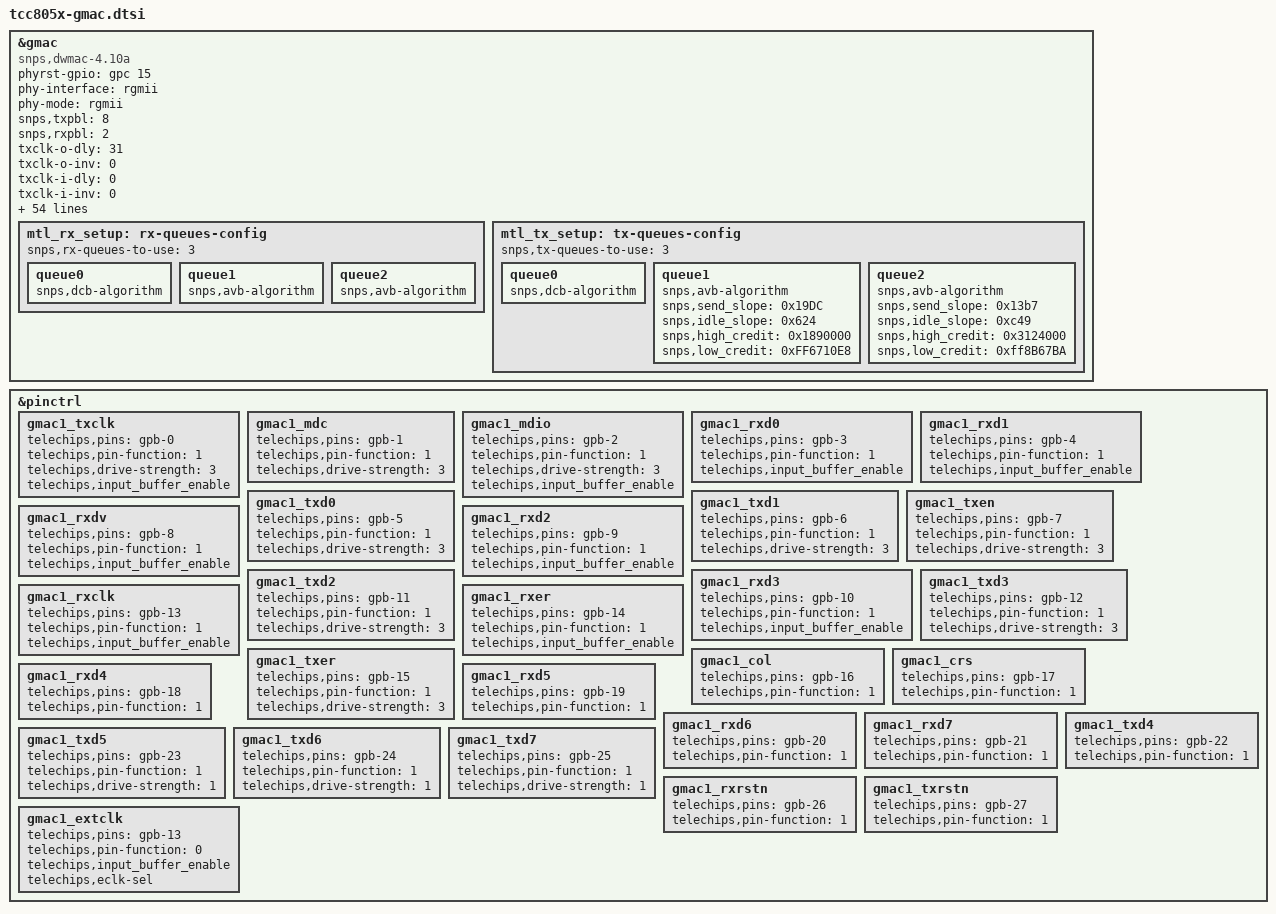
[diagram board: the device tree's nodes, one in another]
// SPDX-License-Identifier: (GPL-2.0-or-later OR MIT)
/*
 * Copyright (C) 2023 Telechips Inc.
 */

&gmac {
	status = "okay";
	compatible = "snps,dwmac-4.10a","telechips,gmac";
	phyrst-gpio = <&gpc 15 0>;
	phy-interface = "rgmii";
	interrupt-names = "macirq";
	phy-mode = "rgmii";
	snps,txpbl = <8>;
	snps,rxpbl = <2>;
	//ecid-mac-addr;
	txclk-o-dly = <31>;
	txclk-o-inv = <0>;
	txclk-i-dly = <0>;
	txclk-i-inv = <0>;
	txen-dly = <0>;
	txer-dly = <0>;
	txd0-dly = <0>;
	txd1-dly = <0>;
	txd2-dly = <0>;
	txd3-dly = <0>;
	txd4-dly = <0>;
	txd5-dly = <0>;
	txd6-dly = <0>;
	txd7-dly = <0>;
	rxclk-i-dly = <0>;
	rxclk-i-inv = <0>;
	rxdv-dly = <0>;
	rxer-dly = <0>;
	rxd0-dly = <0>;
	rxd1-dly = <0>;
	rxd2-dly = <0>;
	rxd3-dly = <0>;
	rxd4-dly = <0>;
	rxd5-dly = <0>;
	rxd6-dly = <0>;
	rxd7-dly = <0>;
	crs-dly = <0>;
	col-dly = <0>;
	pinctrl-names = "default", "mii", "rmii-ext","rmii", "gmii", "rgmii","sleep";
	pinctrl-0 = <>;
	pinctrl-1 = <&gmac1_mdc &gmac1_mdio
		&gmac1_txclk &gmac1_txen &gmac1_txd0 &gmac1_txd1 &gmac1_txd2 &gmac1_txd3
		&gmac1_rxclk &gmac1_rxdv &gmac1_rxd0 &gmac1_rxd1 &gmac1_rxd2 &gmac1_rxd3>;
	pinctrl-2 = <&gmac1_mdc &gmac1_mdio
		&gmac1_txclk &gmac1_txen &gmac1_txd0 &gmac1_txd1
		&gmac1_rxer &gmac1_rxdv &gmac1_rxd0 &gmac1_rxd1 &gmac1_extclk>;
	pinctrl-3 = <&gmac1_mdc &gmac1_mdio
		&gmac1_txclk &gmac1_txen &gmac1_txd0 &gmac1_txd1
		&gmac1_rxer &gmac1_rxdv &gmac1_rxd0 &gmac1_rxd1>;
	pinctrl-4 = <&gmac1_mdc &gmac1_mdio
		&gmac1_txclk &gmac1_txen &gmac1_txd0 &gmac1_txd1 &gmac1_txd2 &gmac1_txd3
		&gmac1_txd4 &gmac1_txd5 &gmac1_txd6 &gmac1_txd7
		&gmac1_rxclk &gmac1_rxdv &gmac1_rxd0 &gmac1_rxd1 &gmac1_rxd2 &gmac1_rxd3
		&gmac1_rxd4 &gmac1_rxd5 &gmac1_rxd6 &gmac1_rxd7>;
	pinctrl-5 = <&gmac1_mdc &gmac1_mdio
		&gmac1_txclk &gmac1_txen &gmac1_txd0 &gmac1_txd1 &gmac1_txd2 &gmac1_txd3
		&gmac1_rxclk &gmac1_rxdv &gmac1_rxd0 &gmac1_rxd1 &gmac1_rxd2 &gmac1_rxd3>;
	pinctrl-6 = <>;
	// telechips,fqtss-enable;
	snps,mtl-tx-config = <&mtl_tx_setup>;
	snps,mtl-rx-config = <&mtl_rx_setup>;

	mtl_rx_setup: rx-queues-config {
		snps,rx-queues-to-use = <3>;
		queue0 {
			snps,dcb-algorithm;
		};
		queue1 {
			snps,avb-algorithm;
		};
		queue2 {
			snps,avb-algorithm;
		};
	};

	mtl_tx_setup: tx-queues-config {
		snps,tx-queues-to-use = <3>;
		queue0 {
			snps,dcb-algorithm;
		};
		queue1 {
			snps,avb-algorithm;
			// 192 Mbps
			snps,send_slope = <0x19DC>;
			snps,idle_slope = <0x624>;
			snps,high_credit = <0x1890000>;
			snps,low_credit = <0xFF6710E8>;
		};
		queue2 {
			snps,avb-algorithm;
			// 384 Mbps
			snps,send_slope = <0x13b7>;
			snps,idle_slope = <0xc49>;
			snps,high_credit = <0x3124000>;
			snps,low_credit = <0xff8B67BA>;
		};
	};
#if 0 /* If using fixed link, enable this */
	fixed-link {
		speed = <1000>;
		full-duplex;
	};
#endif
};

&pinctrl {
	gmac1_txclk: gmac1_txclk {
		telechips,pins = "gpb-0";
		telechips,pin-function = <1>;
		telechips,drive-strength = <3>;
		telechips,input_buffer_enable;
	};

	gmac1_mdc: gmac1_mdc {
		telechips,pins = "gpb-1";
		telechips,pin-function = <1>;
		telechips,drive-strength = <3>;
	};

	gmac1_mdio: gmac1_mdio {
		telechips,pins = "gpb-2";
		telechips,pin-function = <1>;
		telechips,drive-strength = <3>;
		telechips,input_buffer_enable;
	};

	gmac1_rxd0: gmac1_rxd0 {
		telechips,pins = "gpb-3";
		telechips,pin-function = <1>;
		telechips,input_buffer_enable;
	};

	gmac1_rxd1: gmac1_rxd1 {
		telechips,pins = "gpb-4";
		telechips,pin-function = <1>;
		telechips,input_buffer_enable;
	};

	gmac1_txd0: gmac1_txd0 {
		telechips,pins = "gpb-5";
		telechips,pin-function = <1>;
		telechips,drive-strength = <3>;
	};

	gmac1_txd1: gmac1_txd1 {
		telechips,pins = "gpb-6";
		telechips,pin-function = <1>;
		telechips,drive-strength = <3>;
	};

	gmac1_txen: gmac1_txen {
		telechips,pins = "gpb-7";
		telechips,pin-function = <1>;
		telechips,drive-strength = <3>;
	};

	gmac1_rxdv: gmac1_rxdv {
		telechips,pins = "gpb-8";
		telechips,pin-function = <1>;
		telechips,input_buffer_enable;
	};

	gmac1_rxd2: gmac1_rxd2 {
		telechips,pins = "gpb-9";
		telechips,pin-function = <1>;
		telechips,input_buffer_enable;
	};

	gmac1_rxd3: gmac1_rxd3 {
		telechips,pins = "gpb-10";
		telechips,pin-function = <1>;
		telechips,input_buffer_enable;
	};

	gmac1_txd2: gmac1_txd2 {
		telechips,pins = "gpb-11";
		telechips,pin-function = <1>;
		telechips,drive-strength = <3>;
	};

	gmac1_txd3: gmac1_txd3 {
		telechips,pins = "gpb-12";
		telechips,pin-function = <1>;
		telechips,drive-strength = <3>;
	};

	gmac1_rxclk: gmac1_rxclk {
		telechips,pins = "gpb-13";
		telechips,pin-function = <1>;
		telechips,input_buffer_enable;
	};

	gmac1_rxer: gmac1_rxer {
		telechips,pins = "gpb-14";
		telechips,pin-function = <1>;
		telechips,input_buffer_enable;
	};

	gmac1_txer: gmac1_txer {
		telechips,pins = "gpb-15";
		telechips,pin-function = <1>;
		telechips,drive-strength = <3>;
	};

	gmac1_col: gmac1_col {
		telechips,pins = "gpb-16";
		telechips,pin-function = <1>;
	};

	gmac1_crs: gmac1_crs {
		telechips,pins = "gpb-17";
		telechips,pin-function = <1>;
	};


	gmac1_rxd4: gmac1_rxd4 {
		telechips,pins = "gpb-18";
		telechips,pin-function = <1>;
	};

	gmac1_rxd5: gmac1_rxd5 {
		telechips,pins = "gpb-19";
		telechips,pin-function = <1>;
	};

	gmac1_rxd6: gmac1_rxd6 {
		telechips,pins = "gpb-20";
		telechips,pin-function = <1>;
	};

	gmac1_rxd7: gmac1_rxd7 {
		telechips,pins = "gpb-21";
		telechips,pin-function = <1>;
	};

	gmac1_txd4: gmac1_txd4 {
		telechips,pins = "gpb-22";
		telechips,pin-function = <1>;
	};

	gmac1_txd5: gmac1_txd5 {
		telechips,pins = "gpb-23";
		telechips,pin-function = <1>;
		telechips,drive-strength = <1>;
	};

	gmac1_txd6: gmac1_txd6 {
		telechips,pins = "gpb-24";
		telechips,pin-function = <1>;
		telechips,drive-strength = <1>;
	};

	gmac1_txd7: gmac1_txd7 {
		telechips,pins = "gpb-25";
		telechips,pin-function = <1>;
		telechips,drive-strength = <1>;
	};

	gmac1_rxrstn: gmac1_rxrstn {
		telechips,pins = "gpb-26";
		telechips,pin-function = <1>;
	};

	gmac1_txrstn: gmac1_txrstn {
		telechips,pins = "gpb-27";
		telechips,pin-function = <1>;
	};

	gmac1_extclk: gmac1_extclk {
		telechips,pins = "gpb-13";
		telechips,pin-function = <0>;
		telechips,input_buffer_enable;
		telechips,eclk-sel;
	};
};
